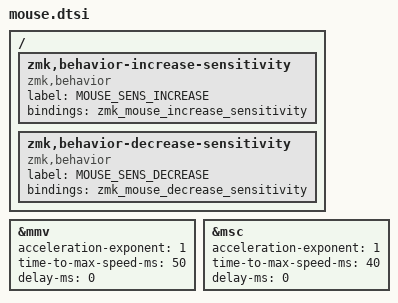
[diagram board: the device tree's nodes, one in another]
#ifndef ZMK_MOUSE_DEFAULT_MOVE_VAL
#define ZMK_MOUSE_DEFAULT_MOVE_VAL 1500 //600
#endif

#ifndef ZMK_MOUSE_DEFAULT_SCRL_VAL
#define ZMK_MOUSE_DEFAULT_SCRL_VAL 20 //10
#endif

#include <dt-bindings/zmk/mouse.h>
#include <behaviors/mouse_keys.dtsi>

&mmv {
  acceleration-exponent = <1>;      // 1
  time-to-max-speed-ms = <50>;    // 40
  delay-ms = <0>;                   // 0
};

&msc {
  acceleration-exponent = <1>;      // 0
  time-to-max-speed-ms = <40>;      // 500
  delay-ms = <0>;                   // 10
};

/ {
    zmk,behavior-increase-sensitivity {
        compatible = "zmk,behavior";
        label = "MOUSE_SENS_INCREASE";
        bindings = <&zmk_mouse_increase_sensitivity>;
    };

    zmk,behavior-decrease-sensitivity {
        compatible = "zmk,behavior";
        label = "MOUSE_SENS_DECREASE";
        bindings = <&zmk_mouse_decrease_sensitivity>;
    };
};

#define U_MS_U &mmv MOVE_UP
#define U_MS_D &mmv MOVE_DOWN
#define U_MS_L &mmv MOVE_LEFT
#define U_MS_R &mmv MOVE_RIGHT
#define U_WH_U &msc SCRL_UP
#define U_WH_D &msc SCRL_DOWN
#define U_WH_L &msc SCRL_LEFT
#define U_WH_R &msc SCRL_RIGHT
#define U_MS_SENS_U &zmk_mouse_increase_sensitivity
#define U_MS_SENS_D &zmk_mouse_decrease_sensitivity
